# PIC32MX150F256L register map
Vendor: Microchip
Registers are 32-bit, read-write, reset 0x0 unless marked. A register's access mark holds for its fields unless they carry their own. Addresses are absolute, and some are shared; only a register's first bit layout is shown; [hi:lo] are bit positions; {n}, {i} and the like mark numbered series.

## DMAC2
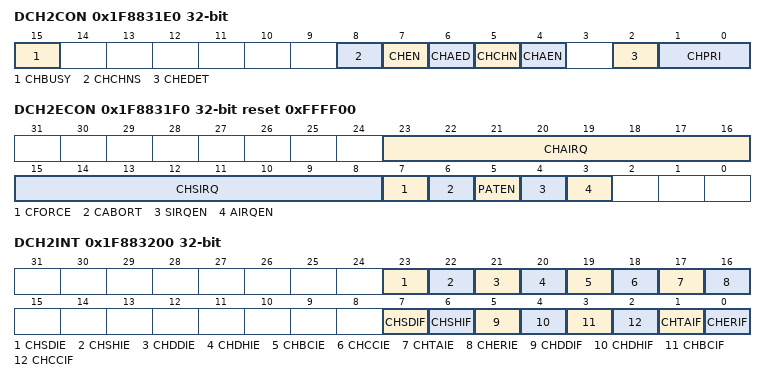
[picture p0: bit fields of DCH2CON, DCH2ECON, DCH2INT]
0x1F8831E0 DCH2CON reset not defined — (power-on value ----------------x------00000-000)
  [15] CHBUSY, [8] CHCHNS, [7] CHEN, [6] CHAED, [5] CHCHN, [4] CHAEN, [2] CHEDET ro, [1:0] CHPRI
0x1F8831F0 DCH2ECON reset 0xFFFF00
  [23:16] CHAIRQ
  [15:8] CHSIRQ
  [7] CFORCE — (can only be set)
  [6] CABORT — (can only be set)
  [5] PATEN
  [4] SIRQEN
  [3] AIRQEN
0x1F883200 DCH2INT
  [23] CHSDIE, [22] CHSHIE, [21] CHDDIE, [20] CHDHIE, [19] CHBCIE, [18] CHCCIE, [17] CHTAIE, [16] CHERIE, [7] CHSDIF, [6] CHSHIF, [5] CHDDIF, [4] CHDHIF, [3] CHBCIF, [2] CHCCIF, [1] CHTAIF, [0] CHERIF
0x1F883210 DCH2SSA reset not defined — (power-on value xxxxxxxxxxxxxxxxxxxxxxxxxxxxxxxx)
0x1F883220 DCH2DSA reset not defined — (power-on value xxxxxxxxxxxxxxxxxxxxxxxxxxxxxxxx)
0x1F883230 DCH2SSIZ reset not defined — (power-on value ----------------xxxxxxxxxxxxxxxx)
  [15:0] CHSSIZ
0x1F883240 DCH2DSIZ reset not defined — (power-on value ----------------xxxxxxxxxxxxxxxx)
  [15:0] CHDSIZ
0x1F883250 DCH2SPTR reset not defined — (power-on value ----------------xxxxxxxxxxxxxxxx)
  [15:0] CHSPTR
0x1F883260 DCH2DPTR ro
  [15:0] CHDPTR
0x1F883270 DCH2CSIZ reset not defined — (power-on value ----------------xxxxxxxxxxxxxxxx)
  [15:0] CHCSIZ
0x1F883280 DCH2CPTR reset not defined — (power-on value ----------------xxxxxxxxxxxxxxxx)
  [15:0] CHCPTR
0x1F883290 DCH2DAT reset not defined — (power-on value ------------------------xxxxxxxx)
  [7:0] DCHPDAT

## DMAC3
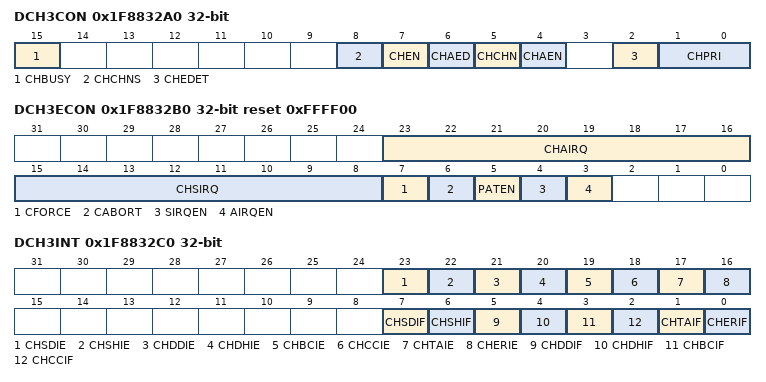
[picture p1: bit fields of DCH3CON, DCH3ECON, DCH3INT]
0x1F8832A0 DCH3CON reset not defined — (power-on value ----------------x------00000-000)
  [15] CHBUSY, [8] CHCHNS, [7] CHEN, [6] CHAED, [5] CHCHN, [4] CHAEN, [2] CHEDET ro, [1:0] CHPRI
0x1F8832B0 DCH3ECON reset 0xFFFF00
  [23:16] CHAIRQ
  [15:8] CHSIRQ
  [7] CFORCE — (can only be set)
  [6] CABORT — (can only be set)
  [5] PATEN
  [4] SIRQEN
  [3] AIRQEN
0x1F8832C0 DCH3INT
  [23] CHSDIE, [22] CHSHIE, [21] CHDDIE, [20] CHDHIE, [19] CHBCIE, [18] CHCCIE, [17] CHTAIE, [16] CHERIE, [7] CHSDIF, [6] CHSHIF, [5] CHDDIF, [4] CHDHIF, [3] CHBCIF, [2] CHCCIF, [1] CHTAIF, [0] CHERIF
0x1F8832D0 DCH3SSA reset not defined — (power-on value xxxxxxxxxxxxxxxxxxxxxxxxxxxxxxxx)
0x1F8832E0 DCH3DSA reset not defined — (power-on value xxxxxxxxxxxxxxxxxxxxxxxxxxxxxxxx)
0x1F8832F0 DCH3SSIZ reset not defined — (power-on value ----------------xxxxxxxxxxxxxxxx)
  [15:0] CHSSIZ
0x1F883300 DCH3DSIZ reset not defined — (power-on value ----------------xxxxxxxxxxxxxxxx)
  [15:0] CHDSIZ
0x1F883310 DCH3SPTR reset not defined — (power-on value ----------------xxxxxxxxxxxxxxxx)
  [15:0] CHSPTR
0x1F883320 DCH3DPTR ro
  [15:0] CHDPTR
0x1F883330 DCH3CSIZ reset not defined — (power-on value ----------------xxxxxxxxxxxxxxxx)
  [15:0] CHCSIZ
0x1F883340 DCH3CPTR reset not defined — (power-on value ----------------xxxxxxxxxxxxxxxx)
  [15:0] CHCPTR
0x1F883350 DCH3DAT reset not defined — (power-on value ------------------------xxxxxxxx)
  [7:0] DCHPDAT

## TRAN_Ports
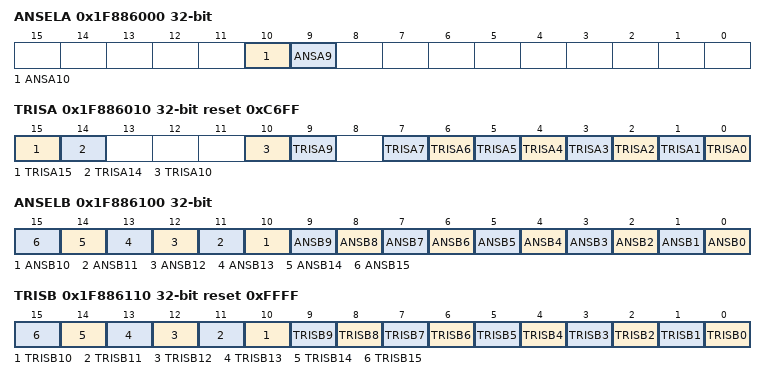
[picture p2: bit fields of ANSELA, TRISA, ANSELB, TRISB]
0x1F886000 ANSELA reset not defined — (power-on value ---------------------xx---------)
  [10] ANSA10, [9] ANSA9
0x1F886010 TRISA reset 0xC6FF
  [15] TRISA15, [14] TRISA14, [10] TRISA10, [9] TRISA9, [n] TRISA{n} (n=0..7)
0x1F886100 ANSELB reset not defined — (power-on value ----------------xxxxxxxxxxxxxxxx)
  [n] ANSB{n} (n=0..15)
0x1F886110 TRISB reset 0xFFFF
  [n] TRISB{n} (n=0..15)
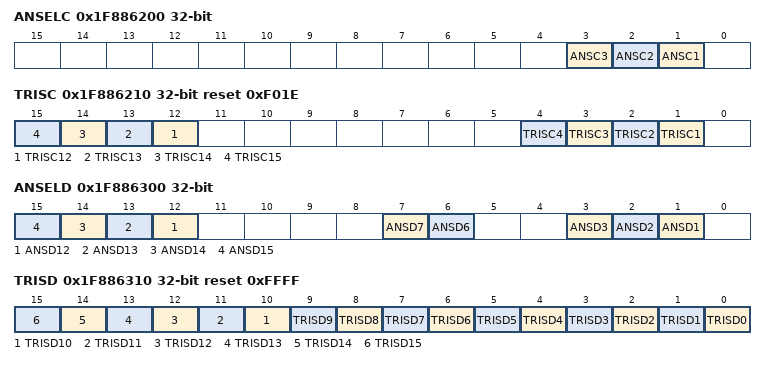
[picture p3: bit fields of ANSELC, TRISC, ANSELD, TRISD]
0x1F886200 ANSELC reset not defined — (power-on value ----------------------------xxx-)
  [3] ANSC3, [2] ANSC2, [1] ANSC1
0x1F886210 TRISC reset 0xF01E
  [n] TRISC{n} (n=12..15), [n] TRISC{n} (n=1..4)
0x1F886300 ANSELD reset not defined — (power-on value ----------------xxxx----xx--xxx-)
  [n] ANSD{n} (n=12..15), [7] ANSD7, [6] ANSD6, [3] ANSD3, [2] ANSD2, [1] ANSD1
0x1F886310 TRISD reset 0xFFFF
  [n] TRISD{n} (n=0..15)
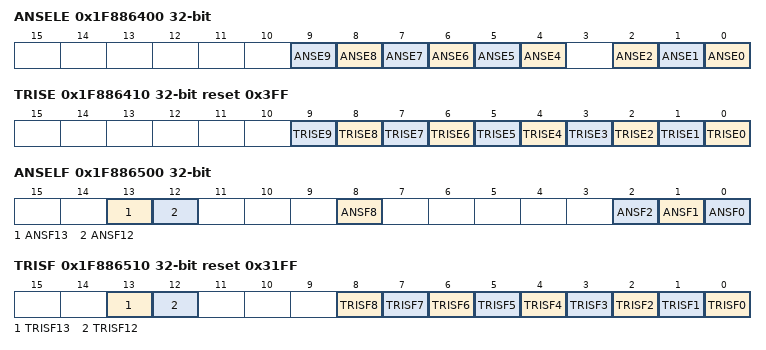
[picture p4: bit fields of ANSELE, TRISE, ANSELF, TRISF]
0x1F886400 ANSELE reset not defined — (power-on value ----------------------xxxxxx-xxx)
  [n] ANSE{n} (n=4..9), [2] ANSE2, [1] ANSE1, [0] ANSE0
0x1F886410 TRISE reset 0x3FF
  [n] TRISE{n} (n=0..9)
0x1F886500 ANSELF reset not defined — (power-on value ------------------xx---x-----xxx)
  [13] ANSF13, [12] ANSF12, [8] ANSF8, [2] ANSF2, [1] ANSF1, [0] ANSF0
0x1F886510 TRISF reset 0x31FF
  [13] TRISF13, [12] TRISF12, [n] TRISF{n} (n=0..8)
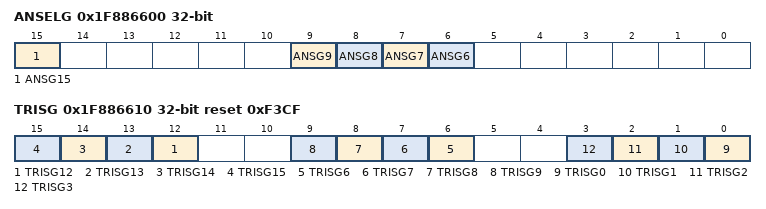
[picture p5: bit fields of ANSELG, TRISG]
0x1F886600 ANSELG reset not defined — (power-on value ----------------x-----xxxx------)
  [15] ANSG15, [n] ANSG{n} (n=6..9)
0x1F886610 TRISG reset 0xF3CF
  [n] TRISG{n} (n=12..15), [n] TRISG{n} (n=6..9), [n] TRISG{n} (n=0..3)
